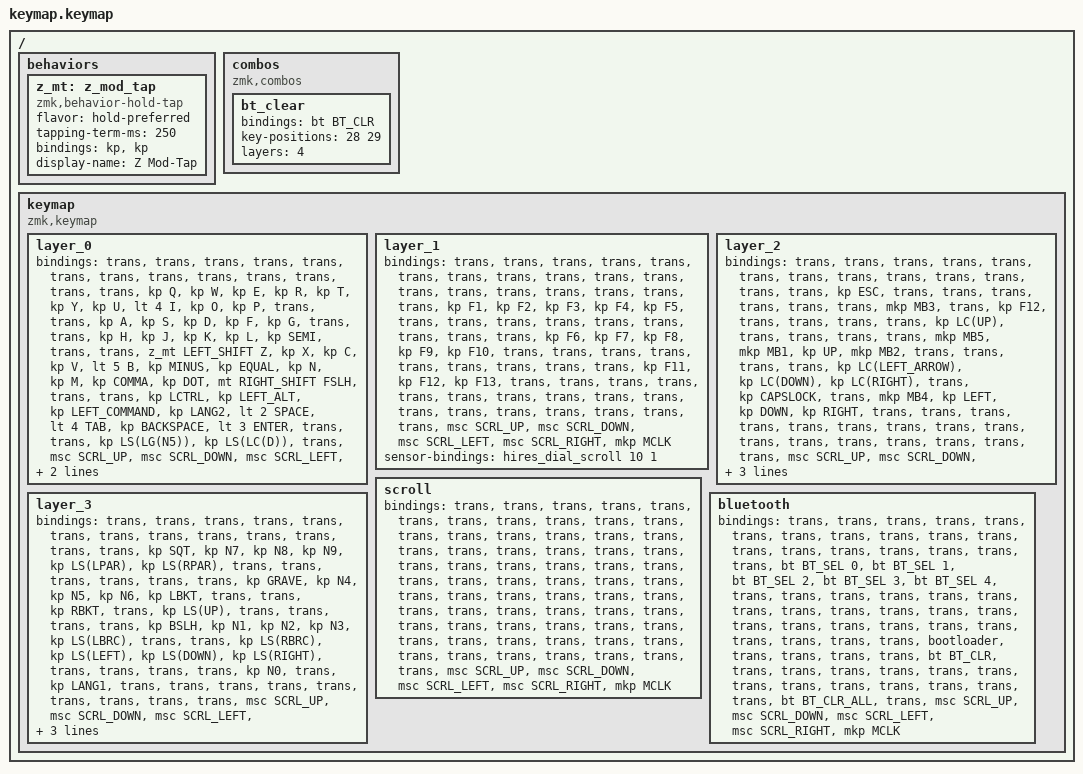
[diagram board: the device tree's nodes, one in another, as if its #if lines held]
#include <behaviors.dtsi>
#include <dt-bindings/zmk/bt.h>
#include <dt-bindings/zmk/keys.h>
#include <dt-bindings/zmk/pointing.h>

#if defined(TORABO_TSUKI_LP_INPUT_HIRES_DIAL)
#include <behaviors/hires_dial.dtsi>
#endif

/ {
    behaviors {
        z_mt: z_mod_tap {
            compatible = "zmk,behavior-hold-tap";
            #binding-cells = <2>;
            flavor = "hold-preferred";
            tapping-term-ms = <250>;
            bindings = <&kp>, <&kp>;
            display-name = "Z Mod-Tap";
        };
    };

    combos {
        compatible = "zmk,combos";

        bt_clear {
            bindings = <&bt BT_CLR>;
            key-positions = <28 29>;
            layers = <4>;
        };
    };

    keymap {
        compatible = "zmk,keymap";

        layer_0 {
            bindings = <
&trans  &trans            &trans        &trans            &trans     &trans                                 &trans       &trans  &trans     &trans          &trans                &trans
&trans  &kp Q             &kp W         &kp E             &kp R      &kp T                                  &kp Y        &kp U   &lt 4 I    &kp O           &kp P                 &trans
&trans  &kp A             &kp S         &kp D             &kp F      &kp G        &trans     &trans         &kp H        &kp J   &kp K      &kp L           &kp SEMI              &trans
&trans  &z_mt LEFT_SHIFT Z  &kp X         &kp C             &kp V      &lt 5 B      &kp MINUS  &kp EQUAL      &kp N        &kp M   &kp COMMA  &kp DOT         &mt RIGHT_SHIFT FSLH  &trans
&trans  &kp LCTRL         &kp LEFT_ALT  &kp LEFT_COMMAND  &kp LANG2  &lt 2 SPACE  &lt 4 TAB  &kp BACKSPACE  &lt 3 ENTER  &trans  &trans     &kp LS(LG(N5))  &kp LS(LC(D))         &trans
#if defined(TORABO_TSUKI_LP_KSCAN_4_DIRECTION_SWITCH)
&msc SCRL_UP &msc SCRL_DOWN &msc SCRL_LEFT &msc SCRL_RIGHT &mkp MCLK
#elif defined(TORABO_TSUKI_LP_INPUT_HIRES_DIAL)
&mkp MCLK
#endif
            >;
        };

        layer_1 {
            bindings = <
&trans  &trans  &trans  &trans  &trans  &trans                  &trans   &trans   &trans   &trans  &trans   &trans
&trans  &trans  &trans  &trans  &trans  &trans                  &kp F1   &kp F2   &kp F3   &kp F4  &kp F5   &trans
&trans  &trans  &trans  &trans  &trans  &trans  &trans  &trans  &kp F6   &kp F7   &kp F8   &kp F9  &kp F10  &trans
&trans  &trans  &trans  &trans  &trans  &trans  &trans  &trans  &kp F11  &kp F12  &kp F13  &trans  &trans   &trans
&trans  &trans  &trans  &trans  &trans  &trans  &trans  &trans  &trans   &trans   &trans   &trans  &trans   &trans
#if defined(TORABO_TSUKI_LP_KSCAN_4_DIRECTION_SWITCH)
&msc SCRL_UP &msc SCRL_DOWN &msc SCRL_LEFT &msc SCRL_RIGHT &mkp MCLK
#elif defined(TORABO_TSUKI_LP_INPUT_HIRES_DIAL)
&mkp MCLK
#endif
            >;
        };

        layer_2 {
            bindings = <
&trans  &trans   &trans              &trans        &trans         &trans                        &trans    &trans    &trans    &trans     &trans   &trans
&trans  &kp ESC  &trans              &trans        &trans         &trans                        &trans    &trans    &mkp MB3  &trans     &kp F12  &trans
&trans  &trans   &trans              &kp LC(UP)    &trans         &trans  &trans        &trans  &mkp MB5  &mkp MB1  &kp UP    &mkp MB2   &trans   &trans
&trans  &trans   &kp LC(LEFT_ARROW)  &kp LC(DOWN)  &kp LC(RIGHT)  &trans  &kp CAPSLOCK  &trans  &mkp MB4  &kp LEFT  &kp DOWN  &kp RIGHT  &trans   &trans
&trans  &trans   &trans              &trans        &trans         &trans  &trans        &trans  &trans    &trans    &trans    &trans     &trans   &trans
#if defined(TORABO_TSUKI_LP_KSCAN_4_DIRECTION_SWITCH)
&msc SCRL_UP &msc SCRL_DOWN &msc SCRL_LEFT &msc SCRL_RIGHT &mkp MCLK
#elif defined(TORABO_TSUKI_LP_INPUT_HIRES_DIAL)
&kp C_MUTE
#endif
            >;
        };

        layer_3 {
            bindings = <
&trans  &trans     &trans  &trans  &trans     &trans                        &trans        &trans        &trans        &trans         &trans  &trans
&trans  &kp SQT    &kp N7  &kp N8  &kp N9     &kp LS(LPAR)                  &kp LS(RPAR)  &trans        &trans        &trans         &trans  &trans
&trans  &kp GRAVE  &kp N4  &kp N5  &kp N6     &kp LBKT      &trans  &trans  &kp RBKT      &trans        &kp LS(UP)    &trans         &trans  &trans
&trans  &kp BSLH   &kp N1  &kp N2  &kp N3     &kp LS(LBRC)  &trans  &trans  &kp LS(RBRC)  &kp LS(LEFT)  &kp LS(DOWN)  &kp LS(RIGHT)  &trans  &trans
&trans  &trans     &kp N0  &trans  &kp LANG1  &trans        &trans  &trans  &trans        &trans        &trans        &trans         &trans  &trans
#if defined(TORABO_TSUKI_LP_KSCAN_4_DIRECTION_SWITCH)
&msc SCRL_UP &msc SCRL_DOWN &msc SCRL_LEFT &msc SCRL_RIGHT &mkp MCLK
#elif defined(TORABO_TSUKI_LP_INPUT_HIRES_DIAL)
&hires_dial_radial_controller_button
#endif
            >;
        };

        scroll {
            bindings = <
&trans  &trans  &trans  &trans  &trans  &trans                  &trans  &trans  &trans  &trans  &trans  &trans
&trans  &trans  &trans  &trans  &trans  &trans                  &trans  &trans  &trans  &trans  &trans  &trans
&trans  &trans  &trans  &trans  &trans  &trans  &trans  &trans  &trans  &trans  &trans  &trans  &trans  &trans
&trans  &trans  &trans  &trans  &trans  &trans  &trans  &trans  &trans  &trans  &trans  &trans  &trans  &trans
&trans  &trans  &trans  &trans  &trans  &trans  &trans  &trans  &trans  &trans  &trans  &trans  &trans  &trans
#if defined(TORABO_TSUKI_LP_KSCAN_4_DIRECTION_SWITCH)
&msc SCRL_UP &msc SCRL_DOWN &msc SCRL_LEFT &msc SCRL_RIGHT &mkp MCLK
#elif defined(TORABO_TSUKI_LP_INPUT_HIRES_DIAL)
&trans
#endif
            >;
        };

        bluetooth {
            bindings = <
&trans  &trans  &trans  &trans  &trans  &trans                       &trans        &trans        &trans        &trans        &trans          &trans
&trans  &trans  &trans  &trans  &trans  &trans                       &bt BT_SEL 0  &bt BT_SEL 1  &bt BT_SEL 2  &bt BT_SEL 3  &bt BT_SEL 4    &trans
&trans  &trans  &trans  &trans  &trans  &trans  &trans  &trans       &trans        &trans        &trans        &trans        &trans          &trans
&trans  &trans  &trans  &trans  &trans  &trans  &trans  &bootloader  &trans        &trans        &trans        &trans        &bt BT_CLR      &trans
&trans  &trans  &trans  &trans  &trans  &trans  &trans  &trans       &trans        &trans        &trans        &trans        &bt BT_CLR_ALL  &trans
#if defined(TORABO_TSUKI_LP_KSCAN_4_DIRECTION_SWITCH)
&msc SCRL_UP &msc SCRL_DOWN &msc SCRL_LEFT &msc SCRL_RIGHT &mkp MCLK
#elif defined(TORABO_TSUKI_LP_INPUT_HIRES_DIAL)
&trans
#endif
            >;
        };
    };
};

#if defined(TORABO_TSUKI_LP_INPUT_HIRES_DIAL)
&{/keymap/layer_0} {
    sensor-bindings = <&hires_dial_scroll 1 1>;
};

&{/keymap/layer_1} {
    sensor-bindings = <&hires_dial_scroll 10 1>;
};

&{/keymap/layer_2} {
    sensor-bindings = <&hires_dial_encoder C_VOL_UP C_VOL_DN>;
};

&{/keymap/layer_3} {
    /* Quarter-speed Radial Controller motion: output/input = 1/4. */
    sensor-bindings = <&hires_dial_radial_controller 4 1>;
};
#endif
